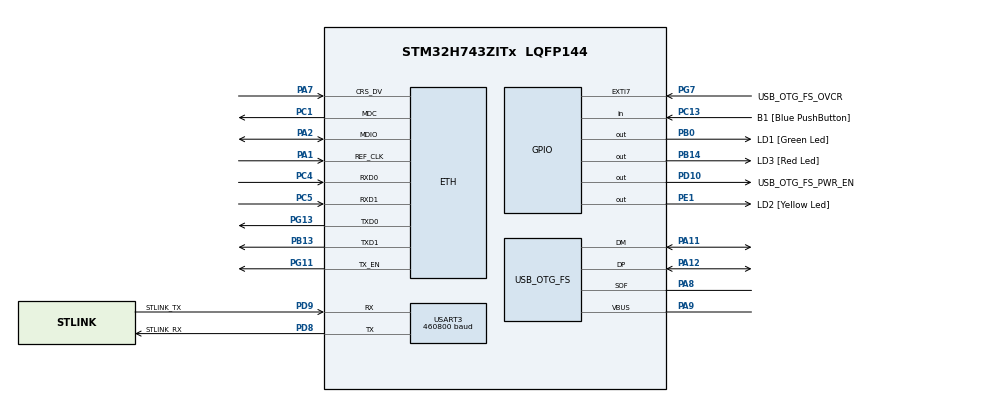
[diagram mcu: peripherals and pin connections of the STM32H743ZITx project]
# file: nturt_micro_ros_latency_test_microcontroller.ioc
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CORTEX_M7.AccessPermission-Cortex_Memory_Protection_Unit_Region0_Settings=MPU_REGION_FULL_ACCESS
CORTEX_M7.BaseAddress-Cortex_Memory_Protection_Unit_Region0_Settings=0x30000000
CORTEX_M7.CPU_DCache=Enabled
CORTEX_M7.CPU_ICache=Enabled
CORTEX_M7.DisableExec-Cortex_Memory_Protection_Unit_Region0_Settings=MPU_INSTRUCTION_ACCESS_DISABLE
CORTEX_M7.Enable-Cortex_Memory_Protection_Unit_Region0_Settings=MPU_REGION_ENABLE
CORTEX_M7.IsShareable-Cortex_Memory_Protection_Unit_Region0_Settings=MPU_ACCESS_SHAREABLE
CORTEX_M7.MPU_Control=MPU_PRIVILEGED_DEFAULT
CORTEX_M7.Size-Cortex_Memory_Protection_Unit_Region0_Settings=MPU_REGION_SIZE_2KB
CORTEX_M7.TypeExtField-Cortex_Memory_Protection_Unit_Region0_Settings=MPU_TEX_LEVEL1
Dma.Request0=USART3_RX
Dma.Request1=USART3_TX
Dma.USART3_RX.0.Direction=DMA_PERIPH_TO_MEMORY
Dma.USART3_RX.0.EventEnable=DISABLE
Dma.USART3_RX.0.FIFOMode=DMA_FIFOMODE_DISABLE
Dma.USART3_RX.0.Instance=DMA1_Stream0
Dma.USART3_RX.0.MemDataAlignment=DMA_MDATAALIGN_BYTE
Dma.USART3_RX.0.MemInc=DMA_MINC_ENABLE
Dma.USART3_RX.0.Mode=DMA_CIRCULAR
Dma.USART3_RX.0.PeriphDataAlignment=DMA_PDATAALIGN_BYTE
Dma.USART3_RX.0.PeriphInc=DMA_PINC_DISABLE
Dma.USART3_RX.0.Polarity=HAL_DMAMUX_REQ_GEN_RISING
Dma.USART3_RX.0.Priority=DMA_PRIORITY_VERY_HIGH
Dma.USART3_RX.0.RequestNumber=1
Dma.USART3_RX.0.SignalID=NONE
Dma.USART3_RX.0.SyncEnable=DISABLE
Dma.USART3_RX.0.SyncPolarity=HAL_DMAMUX_SYNC_NO_EVENT
Dma.USART3_RX.0.SyncRequestNumber=1
Dma.USART3_RX.0.SyncSignalID=NONE
Dma.USART3_TX.1.Direction=DMA_MEMORY_TO_PERIPH
Dma.USART3_TX.1.EventEnable=DISABLE
Dma.USART3_TX.1.FIFOMode=DMA_FIFOMODE_DISABLE
Dma.USART3_TX.1.Instance=DMA1_Stream1
Dma.USART3_TX.1.MemDataAlignment=DMA_MDATAALIGN_BYTE
Dma.USART3_TX.1.MemInc=DMA_MINC_ENABLE
Dma.USART3_TX.1.Mode=DMA_NORMAL
Dma.USART3_TX.1.PeriphDataAlignment=DMA_PDATAALIGN_BYTE
Dma.USART3_TX.1.PeriphInc=DMA_PINC_DISABLE
Dma.USART3_TX.1.Polarity=HAL_DMAMUX_REQ_GEN_RISING
Dma.USART3_TX.1.Priority=DMA_PRIORITY_VERY_HIGH
Dma.USART3_TX.1.RequestNumber=1
Dma.USART3_TX.1.SignalID=NONE
Dma.USART3_TX.1.SyncEnable=DISABLE
Dma.USART3_TX.1.SyncPolarity=HAL_DMAMUX_SYNC_NO_EVENT
Dma.USART3_TX.1.SyncRequestNumber=1
Dma.USART3_TX.1.SyncSignalID=NONE
ETH.MediaInterface=HAL_ETH_RMII_MODE
FREERTOS.Tasks01=defaultTask,24,1024,StartDefaultTask,Default,NULL,Static,defaultTaskBuffer,defaultTaskControlBlock
FREERTOS.configENABLE_FPU=1
FREERTOS.configGENERATE_RUN_TIME_STATS=1
FREERTOS.configUSE_NEWLIB_REENTRANT=0
FREERTOS.configUSE_STATS_FORMATTING_FUNCTIONS=1
FREERTOS.copyHeapFile=1
Mcu.Family=STM32H7
Mcu.Name=STM32H743ZITx
Mcu.Package=LQFP144
NVIC.DMA1_Stream0_IRQn=true\:5\:0\:false\:false\:true\:true\:false\:true\:true
NVIC.DMA1_Stream1_IRQn=true\:5\:0\:false\:false\:true\:true\:false\:true\:true
NVIC.PriorityGroup=NVIC_PRIORITYGROUP_4
NVIC.TIM8_UP_TIM13_IRQn=true\:0\:0\:false\:false\:true\:false\:false\:true\:true
NVIC.TimeBase=TIM8_UP_TIM13_IRQn
NVIC.TimeBaseIP=TIM13
NVIC.USART3_IRQn=true\:5\:0\:false\:false\:true\:true\:true\:true\:true
PA1.Mode=RMII
PA1.Signal=ETH_REF_CLK
PA11.Mode=Device_Only
PA11.Signal=USB_OTG_FS_DM
PA12.Mode=Device_Only
PA12.Signal=USB_OTG_FS_DP
PA2.Mode=RMII
PA2.Signal=ETH_MDIO
PA7.Mode=RMII
PA7.Signal=ETH_CRS_DV
PA8.Mode=Activate_SOF_FS
PA8.Signal=USB_OTG_FS_SOF
PA9.Mode=Activate_VBUS
PA9.Signal=USB_OTG_FS_VBUS
PB0.GPIO_Label=LD1 [Green Led]
PB0.Signal=GPIO_Output
PB13.Mode=RMII
PB13.Signal=ETH_TXD1
PB14.GPIO_Label=LD3 [Red Led]
PB14.Signal=GPIO_Output
PC1.Mode=RMII
PC1.Signal=ETH_MDC
PC13.GPIO_Label=B1 [Blue PushButton]
PC13.Signal=GPIO_Input
PC14-OSC32_IN\ (OSC32_IN).Signal=RCC_OSC32_IN
PC15-OSC32_OUT\ (OSC32_OUT).Signal=RCC_OSC32_OUT
PC4.Mode=RMII
PC4.Signal=ETH_RXD0
PC5.Mode=RMII
PC5.Signal=ETH_RXD1
PD10.GPIO_Label=USB_OTG_FS_PWR_EN
PD10.Signal=GPIO_Output
PD8.GPIO_Label=STLINK_RX
PD8.Mode=Asynchronous
PD8.Signal=USART3_TX
PD9.GPIO_Label=STLINK_TX
PD9.Mode=Asynchronous
PD9.Signal=USART3_RX
PE1.GPIO_Label=LD2 [Yellow Led]
PE1.Signal=GPIO_Output
PG11.Mode=RMII
PG11.Signal=ETH_TX_EN
PG13.Mode=RMII
PG13.Signal=ETH_TXD0
PG7.GPIO_Label=USB_OTG_FS_OVCR
PG7.Signal=GPXTI7
PH0-OSC_IN\ (PH0).Mode=HSE-External-Oscillator
PH0-OSC_IN\ (PH0).Signal=RCC_OSC_IN
PH1-OSC_OUT\ (PH1).Mode=HSE-External-Oscillator
PH1-OSC_OUT\ (PH1).Signal=RCC_OSC_OUT
ProjectManager.HeapSize=0x200
ProjectManager.StackSize=0x400
ProjectManager.TargetToolchain=STM32CubeIDE
RCC.ADCFreq_Value=129000000
RCC.APB1Freq_Value=120000000
RCC.APB2Freq_Value=120000000
RCC.APB3Freq_Value=120000000
RCC.APB4Freq_Value=120000000
RCC.CortexFreq_Value=480000000
RCC.D1PPRE=RCC_APB3_DIV2
RCC.D2PPRE1=RCC_APB1_DIV2
RCC.D2PPRE2=RCC_APB2_DIV2
RCC.D3PPRE=RCC_APB4_DIV2
RCC.DIVM1=4
RCC.DIVN1=60
RCC.DIVQ1=4
RCC.HCLKFreq_Value=240000000
RCC.HPRE=RCC_HCLK_DIV2
RCC.HSE_VALUE=25000000
RCC.PLLFRACN=0
RCC.SYSCLKFreq_VALUE=480000000
RCC.SYSCLKSource=RCC_SYSCLKSOURCE_PLLCLK
RCC.USBCLockSelection=RCC_USBCLKSOURCE_HSI48
RCC.USBFreq_Value=48000000
TIM14.Period=23999
USART3.BaudRate=460800
USART3.VirtualMode-Asynchronous=VM_ASYNC
USB_OTG_FS.VirtualMode=Device_Only
VP_FREERTOS_VS_CMSIS_V2.Mode=CMSIS_V2
VP_SYS_VS_tim13.Mode=TIM13
VP_TIM14_VS_ClockSourceINT.Mode=Enable_Timer
board=NUCLEO-H743ZI2

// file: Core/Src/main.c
/* USER CODE BEGIN Header */
/**
 ******************************************************************************
 * @file           : main.c
 * @brief          : Main program body
 ******************************************************************************
 * @attention
 *
 * <h2><center>&copy; Copyright (c) 2022 STMicroelectronics.
 * All rights reserved.</center></h2>
 *
 * This software component is licensed by ST under BSD 3-Clause license,
 * the "License"; You may not use this file except in compliance with the
 * License. You may obtain a copy of the License at:
 *                        opensource.org/licenses/BSD-3-Clause
 *
 ******************************************************************************
 */
/* USER CODE END Header */
#include "main.h"

#include "cmsis_os.h"
#include "string.h"

/* USER CODE BEGIN Includes */
#include "microros_latency_test.h"
/* USER CODE END Includes */

typedef StaticTask_t osStaticThreadDef_t;

#if defined(__ICCARM__) /*!< IAR Compiler */

#pragma location = 0x30040000
ETH_DMADescTypeDef
    DMARxDscrTab[ETH_RX_DESC_CNT]; /* Ethernet Rx DMA Descriptors */
#pragma location = 0x30040060
ETH_DMADescTypeDef
    DMATxDscrTab[ETH_TX_DESC_CNT]; /* Ethernet Tx DMA Descriptors */
#pragma location = 0x30040200
uint8_t Rx_Buff[ETH_RX_DESC_CNT]
               [ETH_MAX_PACKET_SIZE]; /* Ethernet Receive Buffers */

#elif defined(__CC_ARM) /* MDK ARM Compiler */

__attribute__((at(0x30040000))) ETH_DMADescTypeDef
    DMARxDscrTab[ETH_RX_DESC_CNT]; /* Ethernet Rx DMA Descriptors */
__attribute__((at(0x30040060))) ETH_DMADescTypeDef
    DMATxDscrTab[ETH_TX_DESC_CNT]; /* Ethernet Tx DMA Descriptors */
__attribute__((at(0x30040200))) uint8_t
    Rx_Buff[ETH_RX_DESC_CNT][ETH_MAX_PACKET_SIZE]; /* Ethernet Receive Buffer */

#elif defined(__GNUC__) /* GNU Compiler */

ETH_DMADescTypeDef DMARxDscrTab[ETH_RX_DESC_CNT] __attribute__((
    section(".RxDecripSection"))); /* Ethernet Rx DMA Descriptors */
ETH_DMADescTypeDef DMATxDscrTab[ETH_TX_DESC_CNT] __attribute__((
    section(".TxDecripSection"))); /* Ethernet Tx DMA Descriptors */
uint8_t Rx_Buff[ETH_RX_DESC_CNT][ETH_MAX_PACKET_SIZE]
    __attribute__((section(".RxArraySection"))); /* Ethernet Receive Buffers */

#endif

ETH_TxPacketConfig TxConfig;

ETH_HandleTypeDef heth;

TIM_HandleTypeDef htim14;

UART_HandleTypeDef huart3;
DMA_HandleTypeDef hdma_usart3_rx;
DMA_HandleTypeDef hdma_usart3_tx;

PCD_HandleTypeDef hpcd_USB_OTG_FS;

/* Definitions for defaultTask */
osThreadId_t defaultTaskHandle;
uint32_t defaultTaskBuffer[1024];
osStaticThreadDef_t defaultTaskControlBlock;
const osThreadAttr_t defaultTask_attributes = {
    .name = "defaultTask",
    .stack_mem = &defaultTaskBuffer[0],
    .stack_size = sizeof(defaultTaskBuffer),
    .cb_mem = &defaultTaskControlBlock,
    .cb_size = sizeof(defaultTaskControlBlock),
    .priority = (osPriority_t)osPriorityNormal,
};
/* USER CODE BEGIN PV */
volatile uint32_t freertos_stats_clock_tick;
/* USER CODE END PV */

void SystemClock_Config(void);
static void MPU_Config(void);
static void MX_GPIO_Init(void);
static void MX_DMA_Init(void);
static void MX_USART3_UART_Init(void);
static void MX_USB_OTG_FS_PCD_Init(void);
static void MX_ETH_Init(void);
static void MX_TIM14_Init(void);
void StartDefaultTask(void *argument);

int main(void) {

  /* MPU Configuration--------------------------------------------------------*/
  MPU_Config();

  /* Enable I-Cache---------------------------------------------------------*/
  SCB_EnableICache();

  /* Enable D-Cache---------------------------------------------------------*/
  SCB_EnableDCache();

  /* MCU Configuration--------------------------------------------------------*/

  /* Reset of all peripherals, Initializes the Flash interface and the Systick.
   */
  HAL_Init();

  /* Configure the system clock */
  SystemClock_Config();

  /* Initialize all configured peripherals */
  MX_GPIO_Init();
  MX_DMA_Init();
  MX_USART3_UART_Init();
  MX_USB_OTG_FS_PCD_Init();
  MX_ETH_Init();
  MX_TIM14_Init();

  /* Init scheduler */
  osKernelInitialize();

  /* Create the thread(s) */
  /* creation of defaultTask */
  defaultTaskHandle =
      osThreadNew(StartDefaultTask, NULL, &defaultTask_attributes);

  /* Start scheduler */
  osKernelStart();

  /* We should never get here as control is now taken by the scheduler */
  /* Infinite loop */
  while (1) {

  }
}

void SystemClock_Config(void) {
  RCC_OscInitTypeDef RCC_OscInitStruct = {0};
  RCC_ClkInitTypeDef RCC_ClkInitStruct = {0};
  RCC_PeriphCLKInitTypeDef PeriphClkInitStruct = {0};

  /** Supply configuration update enable
   */
  HAL_PWREx_ConfigSupply(PWR_LDO_SUPPLY);
  /** Configure the main internal regulator output voltage
   */
  __HAL_PWR_VOLTAGESCALING_CONFIG(PWR_REGULATOR_VOLTAGE_SCALE0);

  while (!__HAL_PWR_GET_FLAG(PWR_FLAG_VOSRDY)) {
  }
  /** Initializes the RCC Oscillators according to the specified parameters
   * in the RCC_OscInitTypeDef structure.
   */
  RCC_OscInitStruct.OscillatorType =
      RCC_OSCILLATORTYPE_HSI48 | RCC_OSCILLATORTYPE_HSI;
  RCC_OscInitStruct.HSIState = RCC_HSI_DIV1;
  RCC_OscInitStruct.HSICalibrationValue = RCC_HSICALIBRATION_DEFAULT;
  RCC_OscInitStruct.HSI48State = RCC_HSI48_ON;
  RCC_OscInitStruct.PLL.PLLState = RCC_PLL_ON;
  RCC_OscInitStruct.PLL.PLLSource = RCC_PLLSOURCE_HSI;
  RCC_OscInitStruct.PLL.PLLM = 4;
  RCC_OscInitStruct.PLL.PLLN = 60;
  RCC_OscInitStruct.PLL.PLLP = 2;
  RCC_OscInitStruct.PLL.PLLQ = 4;
  RCC_OscInitStruct.PLL.PLLR = 2;
  RCC_OscInitStruct.PLL.PLLRGE = RCC_PLL1VCIRANGE_3;
  RCC_OscInitStruct.PLL.PLLVCOSEL = RCC_PLL1VCOWIDE;
  RCC_OscInitStruct.PLL.PLLFRACN = 0;
  if (HAL_RCC_OscConfig(&RCC_OscInitStruct) != HAL_OK) {
    Error_Handler();
  }
  /** Initializes the CPU, AHB and APB buses clocks
   */
  RCC_ClkInitStruct.ClockType = RCC_CLOCKTYPE_HCLK | RCC_CLOCKTYPE_SYSCLK |
                                RCC_CLOCKTYPE_PCLK1 | RCC_CLOCKTYPE_PCLK2 |
                                RCC_CLOCKTYPE_D3PCLK1 | RCC_CLOCKTYPE_D1PCLK1;
  RCC_ClkInitStruct.SYSCLKSource = RCC_SYSCLKSOURCE_PLLCLK;
  RCC_ClkInitStruct.SYSCLKDivider = RCC_SYSCLK_DIV1;
  RCC_ClkInitStruct.AHBCLKDivider = RCC_HCLK_DIV2;
  RCC_ClkInitStruct.APB3CLKDivider = RCC_APB3_DIV2;
  RCC_ClkInitStruct.APB1CLKDivider = RCC_APB1_DIV2;
  RCC_ClkInitStruct.APB2CLKDivider = RCC_APB2_DIV2;
  RCC_ClkInitStruct.APB4CLKDivider = RCC_APB4_DIV2;

  if (HAL_RCC_ClockConfig(&RCC_ClkInitStruct, FLASH_LATENCY_4) != HAL_OK) {
    Error_Handler();
  }
  PeriphClkInitStruct.PeriphClockSelection =
      RCC_PERIPHCLK_USART3 | RCC_PERIPHCLK_USB;
  PeriphClkInitStruct.Usart234578ClockSelection =
      RCC_USART234578CLKSOURCE_D2PCLK1;
  PeriphClkInitStruct.UsbClockSelection = RCC_USBCLKSOURCE_HSI48;
  if (HAL_RCCEx_PeriphCLKConfig(&PeriphClkInitStruct) != HAL_OK) {
    Error_Handler();
  }
  /** Enable USB Voltage detector
   */
  HAL_PWREx_EnableUSBVoltageDetector();
}

static void MX_ETH_Init(void) {

  heth.Instance = ETH;
  heth.Init.MACAddr[0] = 0x00;
  heth.Init.MACAddr[1] = 0x80;
  heth.Init.MACAddr[2] = 0xE1;
  heth.Init.MACAddr[3] = 0x00;
  heth.Init.MACAddr[4] = 0x00;
  heth.Init.MACAddr[5] = 0x00;
  heth.Init.MediaInterface = HAL_ETH_RMII_MODE;
  heth.Init.TxDesc = DMATxDscrTab;
  heth.Init.RxDesc = DMARxDscrTab;
  heth.Init.RxBuffLen = 1524;

  if (HAL_ETH_Init(&heth) != HAL_OK) {
    Error_Handler();
  }

  memset(&TxConfig, 0, sizeof(ETH_TxPacketConfig));
  TxConfig.Attributes =
      ETH_TX_PACKETS_FEATURES_CSUM | ETH_TX_PACKETS_FEATURES_CRCPAD;
  TxConfig.ChecksumCtrl = ETH_CHECKSUM_IPHDR_PAYLOAD_INSERT_PHDR_CALC;
  TxConfig.CRCPadCtrl = ETH_CRC_PAD_INSERT;
}

static void MX_TIM14_Init(void) {

  htim14.Instance = TIM14;
  htim14.Init.Prescaler = 0;
  htim14.Init.CounterMode = TIM_COUNTERMODE_UP;
  htim14.Init.Period = 23999;
  htim14.Init.ClockDivision = TIM_CLOCKDIVISION_DIV1;
  htim14.Init.AutoReloadPreload = TIM_AUTORELOAD_PRELOAD_DISABLE;
  if (HAL_TIM_Base_Init(&htim14) != HAL_OK) {
    Error_Handler();
  }
}

static void MX_USART3_UART_Init(void) {

  huart3.Instance = USART3;
  huart3.Init.BaudRate = 460800;
  huart3.Init.WordLength = UART_WORDLENGTH_8B;
  huart3.Init.StopBits = UART_STOPBITS_1;
  huart3.Init.Parity = UART_PARITY_NONE;
  huart3.Init.Mode = UART_MODE_TX_RX;
  huart3.Init.HwFlowCtl = UART_HWCONTROL_NONE;
  huart3.Init.OverSampling = UART_OVERSAMPLING_16;
  huart3.Init.OneBitSampling = UART_ONE_BIT_SAMPLE_DISABLE;
  huart3.Init.ClockPrescaler = UART_PRESCALER_DIV1;
  huart3.AdvancedInit.AdvFeatureInit = UART_ADVFEATURE_NO_INIT;
  if (HAL_UART_Init(&huart3) != HAL_OK) {
    Error_Handler();
  }
  if (HAL_UARTEx_SetTxFifoThreshold(&huart3, UART_TXFIFO_THRESHOLD_1_8) !=
      HAL_OK) {
    Error_Handler();
  }
  if (HAL_UARTEx_SetRxFifoThreshold(&huart3, UART_RXFIFO_THRESHOLD_1_8) !=
      HAL_OK) {
    Error_Handler();
  }
  if (HAL_UARTEx_DisableFifoMode(&huart3) != HAL_OK) {
    Error_Handler();
  }
}

static void MX_USB_OTG_FS_PCD_Init(void) {

  hpcd_USB_OTG_FS.Instance = USB_OTG_FS;
  hpcd_USB_OTG_FS.Init.dev_endpoints = 9;
  hpcd_USB_OTG_FS.Init.speed = PCD_SPEED_FULL;
  hpcd_USB_OTG_FS.Init.dma_enable = DISABLE;
  hpcd_USB_OTG_FS.Init.phy_itface = PCD_PHY_EMBEDDED;
  hpcd_USB_OTG_FS.Init.Sof_enable = ENABLE;
  hpcd_USB_OTG_FS.Init.low_power_enable = DISABLE;
  hpcd_USB_OTG_FS.Init.lpm_enable = DISABLE;
  hpcd_USB_OTG_FS.Init.battery_charging_enable = ENABLE;
  hpcd_USB_OTG_FS.Init.vbus_sensing_enable = ENABLE;
  hpcd_USB_OTG_FS.Init.use_dedicated_ep1 = DISABLE;
  if (HAL_PCD_Init(&hpcd_USB_OTG_FS) != HAL_OK) {
    Error_Handler();
  }
}

static void MX_DMA_Init(void) {
  /* DMA controller clock enable */
  __HAL_RCC_DMA1_CLK_ENABLE();

  /* DMA interrupt init */
  /* DMA1_Stream0_IRQn interrupt configuration */
  HAL_NVIC_SetPriority(DMA1_Stream0_IRQn, 5, 0);
  HAL_NVIC_EnableIRQ(DMA1_Stream0_IRQn);
  /* DMA1_Stream1_IRQn interrupt configuration */
  HAL_NVIC_SetPriority(DMA1_Stream1_IRQn, 5, 0);
  HAL_NVIC_EnableIRQ(DMA1_Stream1_IRQn);
}

static void MX_GPIO_Init(void) {
  GPIO_InitTypeDef GPIO_InitStruct = {0};

  /* GPIO Ports Clock Enable */
  __HAL_RCC_GPIOC_CLK_ENABLE();
  __HAL_RCC_GPIOH_CLK_ENABLE();
  __HAL_RCC_GPIOA_CLK_ENABLE();
  __HAL_RCC_GPIOB_CLK_ENABLE();
  __HAL_RCC_GPIOD_CLK_ENABLE();
  __HAL_RCC_GPIOG_CLK_ENABLE();
  __HAL_RCC_GPIOE_CLK_ENABLE();

  /*Configure GPIO pin Output Level */
  HAL_GPIO_WritePin(GPIOB, LD1_Pin | LD3_Pin, GPIO_PIN_RESET);

  /*Configure GPIO pin Output Level */
  HAL_GPIO_WritePin(USB_OTG_FS_PWR_EN_GPIO_Port, USB_OTG_FS_PWR_EN_Pin,
                    GPIO_PIN_RESET);

  /*Configure GPIO pin Output Level */
  HAL_GPIO_WritePin(LD2_GPIO_Port, LD2_Pin, GPIO_PIN_RESET);

  /*Configure GPIO pin : B1_Pin */
  GPIO_InitStruct.Pin = B1_Pin;
  GPIO_InitStruct.Mode = GPIO_MODE_INPUT;
  GPIO_InitStruct.Pull = GPIO_NOPULL;
  HAL_GPIO_Init(B1_GPIO_Port, &GPIO_InitStruct);

  /*Configure GPIO pins : LD1_Pin LD3_Pin */
  GPIO_InitStruct.Pin = LD1_Pin | LD3_Pin;
  GPIO_InitStruct.Mode = GPIO_MODE_OUTPUT_PP;
  GPIO_InitStruct.Pull = GPIO_NOPULL;
  GPIO_InitStruct.Speed = GPIO_SPEED_FREQ_LOW;
  HAL_GPIO_Init(GPIOB, &GPIO_InitStruct);

  /*Configure GPIO pin : USB_OTG_FS_PWR_EN_Pin */
  GPIO_InitStruct.Pin = USB_OTG_FS_PWR_EN_Pin;
  GPIO_InitStruct.Mode = GPIO_MODE_OUTPUT_PP;
  GPIO_InitStruct.Pull = GPIO_NOPULL;
  GPIO_InitStruct.Speed = GPIO_SPEED_FREQ_LOW;
  HAL_GPIO_Init(USB_OTG_FS_PWR_EN_GPIO_Port, &GPIO_InitStruct);

  /*Configure GPIO pin : USB_OTG_FS_OVCR_Pin */
  GPIO_InitStruct.Pin = USB_OTG_FS_OVCR_Pin;
  GPIO_InitStruct.Mode = GPIO_MODE_IT_RISING;
  GPIO_InitStruct.Pull = GPIO_NOPULL;
  HAL_GPIO_Init(USB_OTG_FS_OVCR_GPIO_Port, &GPIO_InitStruct);

  /*Configure GPIO pin : LD2_Pin */
  GPIO_InitStruct.Pin = LD2_Pin;
  GPIO_InitStruct.Mode = GPIO_MODE_OUTPUT_PP;
  GPIO_InitStruct.Pull = GPIO_NOPULL;
  GPIO_InitStruct.Speed = GPIO_SPEED_FREQ_LOW;
  HAL_GPIO_Init(LD2_GPIO_Port, &GPIO_InitStruct);
}

/* USER CODE BEGIN 4 */
void configureTimerForRunTimeStats(void) {
  freertos_stats_clock_tick = 0;
  HAL_TIM_Base_Start_IT(&htim14);
}

unsigned long getRunTimeCounterValue(void) { return freertos_stats_clock_tick; }
/* USER CODE END 4 */

void StartDefaultTask(void *argument) {
  /* USER CODE BEGIN 5 */
  start_microros_latency_test_task(argument);
  /* USER CODE END 5 */
}

/* MPU Configuration */

void MPU_Config(void) {
  MPU_Region_InitTypeDef MPU_InitStruct = {0};

  /* Disables the MPU */
  HAL_MPU_Disable();
  /** Initializes and configures the Region and the memory to be protected
   */
  MPU_InitStruct.Enable = MPU_REGION_ENABLE;
  MPU_InitStruct.Number = MPU_REGION_NUMBER0;
  MPU_InitStruct.BaseAddress = 0x30000000;
  MPU_InitStruct.Size = MPU_REGION_SIZE_2KB;
  MPU_InitStruct.SubRegionDisable = 0x0;
  MPU_InitStruct.TypeExtField = MPU_TEX_LEVEL1;
  MPU_InitStruct.AccessPermission = MPU_REGION_FULL_ACCESS;
  MPU_InitStruct.DisableExec = MPU_INSTRUCTION_ACCESS_DISABLE;
  MPU_InitStruct.IsShareable = MPU_ACCESS_SHAREABLE;
  MPU_InitStruct.IsCacheable = MPU_ACCESS_NOT_CACHEABLE;
  MPU_InitStruct.IsBufferable = MPU_ACCESS_NOT_BUFFERABLE;

  HAL_MPU_ConfigRegion(&MPU_InitStruct);
  /* Enables the MPU */
  HAL_MPU_Enable(MPU_PRIVILEGED_DEFAULT);
}
void HAL_TIM_PeriodElapsedCallback(TIM_HandleTypeDef *htim) {
  if (htim->Instance == TIM13) {
    HAL_IncTick();
  }
}

void Error_Handler(void) {
  /* USER CODE BEGIN Error_Handler_Debug */
  __disable_irq();

  // light up all three leds to indicate hard fault
  HAL_GPIO_WritePin(LD1_GPIO_Port, LD1_Pin, GPIO_PIN_SET);
  HAL_GPIO_WritePin(LD2_GPIO_Port, LD2_Pin, GPIO_PIN_SET);
  HAL_GPIO_WritePin(LD3_GPIO_Port, LD3_Pin, GPIO_PIN_SET);
  while (1) {
  }
  /* USER CODE END Error_Handler_Debug */
}

#ifdef USE_FULL_ASSERT
/**
 * @brief  Reports the name of the source file and the source line number
 *         where the assert_param error has occurred.
 * @param  file: pointer to the source file name
 * @param  line: assert_param error line source number
 * @retval None
 */
void assert_failed(uint8_t *file, uint32_t line) {
  /* USER CODE BEGIN 6 */
  /* User can add his own implementation to report the file name and line
     number, ex: printf("Wrong parameters value: file %s on line %d\r\n", file,
     line) */
  /* USER CODE END 6 */
}
#endif /* USE_FULL_ASSERT */

/************************ (C) COPYRIGHT STMicroelectronics *****END OF FILE****/

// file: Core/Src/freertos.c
/* USER CODE BEGIN Header */
/**
  ******************************************************************************
  * File Name          : freertos.c
  * Description        : Code for freertos applications
  ******************************************************************************
  * @attention
  *
  * <h2><center>&copy; Copyright (c) 2022 STMicroelectronics.
  * All rights reserved.</center></h2>
  *
  * This software component is licensed by ST under Ultimate Liberty license
  * SLA0044, the "License"; You may not use this file except in compliance with
  * the License. You may obtain a copy of the License at:
  *                             www.st.com/SLA0044
  *
  ******************************************************************************
  */
/* USER CODE END Header */

#include "FreeRTOS.h"
#include "task.h"
#include "main.h"

/* Hook prototypes */
void configureTimerForRunTimeStats(void);
unsigned long getRunTimeCounterValue(void);

/* USER CODE BEGIN 1 */
/* Functions needed when configGENERATE_RUN_TIME_STATS is on */
__weak void configureTimerForRunTimeStats(void)
{

}

__weak unsigned long getRunTimeCounterValue(void)
{
return 0;
}
/* USER CODE END 1 */

/************************ (C) COPYRIGHT STMicroelectronics *****END OF FILE****/
